AUTOSAR XML (schema 00054)
package /AUTOSAR/Platform/BaseTypes
  7 x base type, all with category=FIXED_LENGTH:
    boolean_bt: base-type-size=8, base-type-encoding=BOOLEAN
    uint8_bt: base-type-size=8, base-type-encoding=NONE
    uint16_bt: base-type-size=16, base-type-encoding=NONE
    uint32_bt: base-type-size=32, base-type-encoding=NONE
    sint8_bt: base-type-size=8, base-type-encoding=2C
    sint16_bt: base-type-size=16, base-type-encoding=2C
    sint32_bt: base-type-size=32, base-type-encoding=2C
package /AUTOSAR/Platform/ImplementationDataTypes
  7 x impl type, all with category=VALUE:
    boolean_T: base-type=boolean_bt
    uint8_T: base-type=uint8_bt
    uint16_T: base-type=uint16_bt
    uint32_T: base-type=uint32_bt
    sint8_T: base-type=sint8_bt
    sint16_T: base-type=sint16_bt
    sint32_T: base-type=sint32_bt
package /Taktflow/System
  system TaktflowSystem: category=SYSTEM_EXTRACT
package /Taktflow/Communication
  can cluster CAN_500k: baudrate=500000, protocol-name=CAN
    can physical channel CAN_Physical: comm-connectors=[CVC_Conn, FZC_Conn, RZC_Conn, SC_Conn, BCM_Conn, ICU_Conn, TCU_Conn, Tester_Conn, Plant_Sim_Conn]
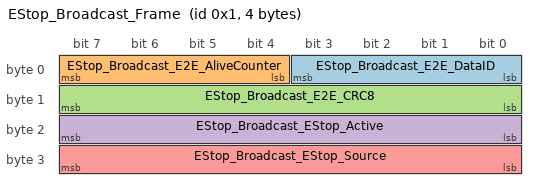
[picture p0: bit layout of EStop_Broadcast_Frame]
      frame EStop_Broadcast_Frame: id 0x1, frame-length=4, can-addressing-mode=STANDARD, can-frame-rx-behavior=CAN-20, can-frame-tx-behavior=CAN-20
        pdu EStop_Broadcast: length=4
          signal EStop_Broadcast_E2E_DataID: start 0, 4 bit, little-endian, data-type-policy=OVERRIDE, transfer-property=PENDING
          signal EStop_Broadcast_E2E_AliveCounter: start 4, 4 bit, little-endian, data-type-policy=OVERRIDE, transfer-property=PENDING
          signal EStop_Broadcast_E2E_CRC8: start 8, 8 bit, little-endian, data-type-policy=OVERRIDE, transfer-property=PENDING
          signal EStop_Broadcast_EStop_Active: start 16, 8 bit, little-endian, data-type-policy=OVERRIDE, transfer-property=PENDING
          signal EStop_Broadcast_EStop_Source: start 24, 8 bit, little-endian, data-type-policy=OVERRIDE, transfer-property=PENDING
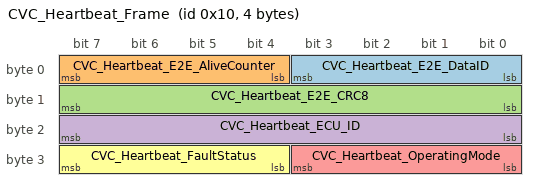
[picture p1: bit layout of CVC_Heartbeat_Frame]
      frame CVC_Heartbeat_Frame: id 0x10, frame-length=4, can-addressing-mode=STANDARD, can-frame-rx-behavior=CAN-20, can-frame-tx-behavior=CAN-20
        pdu CVC_Heartbeat: length=4
          signal CVC_Heartbeat_E2E_DataID: start 0, 4 bit, little-endian, data-type-policy=OVERRIDE, transfer-property=PENDING
          signal CVC_Heartbeat_E2E_AliveCounter: start 4, 4 bit, little-endian, data-type-policy=OVERRIDE, transfer-property=PENDING
          signal CVC_Heartbeat_E2E_CRC8: start 8, 8 bit, little-endian, data-type-policy=OVERRIDE, transfer-property=PENDING
          signal CVC_Heartbeat_ECU_ID: start 16, 8 bit, little-endian, data-type-policy=OVERRIDE, transfer-property=PENDING
          signal CVC_Heartbeat_OperatingMode: start 24, 4 bit, little-endian, data-type-policy=OVERRIDE, transfer-property=PENDING
          signal CVC_Heartbeat_FaultStatus: start 28, 4 bit, little-endian, data-type-policy=OVERRIDE, transfer-property=PENDING
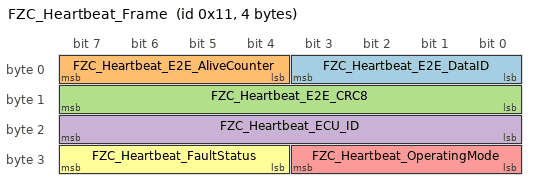
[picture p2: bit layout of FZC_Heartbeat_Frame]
      frame FZC_Heartbeat_Frame: id 0x11, frame-length=4, can-addressing-mode=STANDARD, can-frame-rx-behavior=CAN-20, can-frame-tx-behavior=CAN-20
        pdu FZC_Heartbeat: length=4
          signal FZC_Heartbeat_E2E_DataID: start 0, 4 bit, little-endian, data-type-policy=OVERRIDE, transfer-property=PENDING
          signal FZC_Heartbeat_E2E_AliveCounter: start 4, 4 bit, little-endian, data-type-policy=OVERRIDE, transfer-property=PENDING
          signal FZC_Heartbeat_E2E_CRC8: start 8, 8 bit, little-endian, data-type-policy=OVERRIDE, transfer-property=PENDING
          signal FZC_Heartbeat_ECU_ID: start 16, 8 bit, little-endian, data-type-policy=OVERRIDE, transfer-property=PENDING
          signal FZC_Heartbeat_OperatingMode: start 24, 4 bit, little-endian, data-type-policy=OVERRIDE, transfer-property=PENDING
          signal FZC_Heartbeat_FaultStatus: start 28, 4 bit, little-endian, data-type-policy=OVERRIDE, transfer-property=PENDING
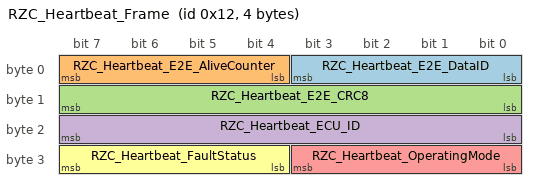
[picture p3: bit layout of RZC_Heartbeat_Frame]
      frame RZC_Heartbeat_Frame: id 0x12, frame-length=4, can-addressing-mode=STANDARD, can-frame-rx-behavior=CAN-20, can-frame-tx-behavior=CAN-20
        pdu RZC_Heartbeat: length=4
          signal RZC_Heartbeat_E2E_DataID: start 0, 4 bit, little-endian, data-type-policy=OVERRIDE, transfer-property=PENDING
          signal RZC_Heartbeat_E2E_AliveCounter: start 4, 4 bit, little-endian, data-type-policy=OVERRIDE, transfer-property=PENDING
          signal RZC_Heartbeat_E2E_CRC8: start 8, 8 bit, little-endian, data-type-policy=OVERRIDE, transfer-property=PENDING
          signal RZC_Heartbeat_ECU_ID: start 16, 8 bit, little-endian, data-type-policy=OVERRIDE, transfer-property=PENDING
          signal RZC_Heartbeat_OperatingMode: start 24, 4 bit, little-endian, data-type-policy=OVERRIDE, transfer-property=PENDING
          signal RZC_Heartbeat_FaultStatus: start 28, 4 bit, little-endian, data-type-policy=OVERRIDE, transfer-property=PENDING
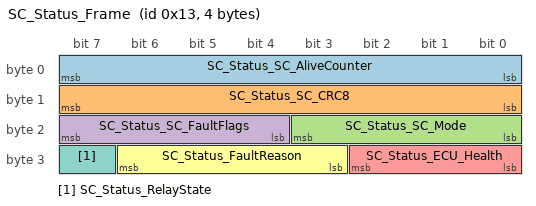
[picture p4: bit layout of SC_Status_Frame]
      frame SC_Status_Frame: id 0x13, frame-length=4, can-addressing-mode=STANDARD, can-frame-rx-behavior=CAN-20, can-frame-tx-behavior=CAN-20
        pdu SC_Status: length=4
          signal SC_Status_SC_AliveCounter: start 0, 8 bit, little-endian, data-type-policy=OVERRIDE, transfer-property=PENDING
          signal SC_Status_SC_CRC8: start 8, 8 bit, little-endian, data-type-policy=OVERRIDE, transfer-property=PENDING
          signal SC_Status_SC_Mode: start 16, 4 bit, little-endian, data-type-policy=OVERRIDE, transfer-property=PENDING
          signal SC_Status_SC_FaultFlags: start 20, 4 bit, little-endian, data-type-policy=OVERRIDE, transfer-property=PENDING
          signal SC_Status_ECU_Health: start 24, 3 bit, little-endian, data-type-policy=OVERRIDE, transfer-property=PENDING
          signal SC_Status_FaultReason: start 27, 4 bit, little-endian, data-type-policy=OVERRIDE, transfer-property=PENDING
          signal SC_Status_RelayState: start 31, 1 bit, little-endian, data-type-policy=OVERRIDE, transfer-property=PENDING
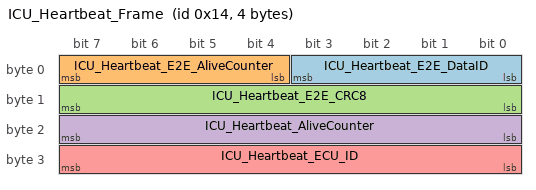
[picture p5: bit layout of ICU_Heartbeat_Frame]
      frame ICU_Heartbeat_Frame: id 0x14, frame-length=4, can-addressing-mode=STANDARD, can-frame-rx-behavior=CAN-20, can-frame-tx-behavior=CAN-20
        pdu ICU_Heartbeat: length=4
          signal ICU_Heartbeat_E2E_DataID: start 0, 4 bit, little-endian, data-type-policy=OVERRIDE, transfer-property=PENDING
          signal ICU_Heartbeat_E2E_AliveCounter: start 4, 4 bit, little-endian, data-type-policy=OVERRIDE, transfer-property=PENDING
          signal ICU_Heartbeat_E2E_CRC8: start 8, 8 bit, little-endian, data-type-policy=OVERRIDE, transfer-property=PENDING
          signal ICU_Heartbeat_AliveCounter: start 16, 8 bit, little-endian, data-type-policy=OVERRIDE, transfer-property=PENDING
          signal ICU_Heartbeat_ECU_ID: start 24, 8 bit, little-endian, data-type-policy=OVERRIDE, transfer-property=PENDING
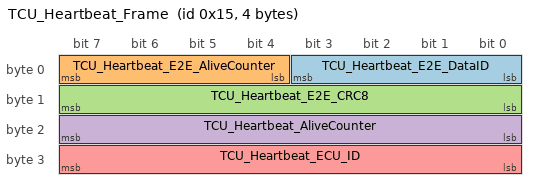
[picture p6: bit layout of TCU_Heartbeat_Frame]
      frame TCU_Heartbeat_Frame: id 0x15, frame-length=4, can-addressing-mode=STANDARD, can-frame-rx-behavior=CAN-20, can-frame-tx-behavior=CAN-20
        pdu TCU_Heartbeat: length=4
          signal TCU_Heartbeat_E2E_DataID: start 0, 4 bit, little-endian, data-type-policy=OVERRIDE, transfer-property=PENDING
          signal TCU_Heartbeat_E2E_AliveCounter: start 4, 4 bit, little-endian, data-type-policy=OVERRIDE, transfer-property=PENDING
          signal TCU_Heartbeat_E2E_CRC8: start 8, 8 bit, little-endian, data-type-policy=OVERRIDE, transfer-property=PENDING
          signal TCU_Heartbeat_AliveCounter: start 16, 8 bit, little-endian, data-type-policy=OVERRIDE, transfer-property=PENDING
          signal TCU_Heartbeat_ECU_ID: start 24, 8 bit, little-endian, data-type-policy=OVERRIDE, transfer-property=PENDING
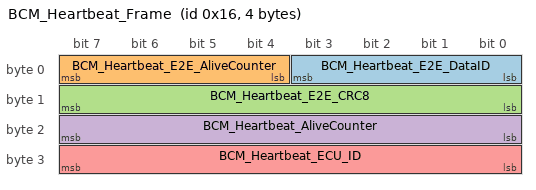
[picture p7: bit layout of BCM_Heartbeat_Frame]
      frame BCM_Heartbeat_Frame: id 0x16, frame-length=4, can-addressing-mode=STANDARD, can-frame-rx-behavior=CAN-20, can-frame-tx-behavior=CAN-20
        pdu BCM_Heartbeat: length=4
          signal BCM_Heartbeat_E2E_DataID: start 0, 4 bit, little-endian, data-type-policy=OVERRIDE, transfer-property=PENDING
          signal BCM_Heartbeat_E2E_AliveCounter: start 4, 4 bit, little-endian, data-type-policy=OVERRIDE, transfer-property=PENDING
          signal BCM_Heartbeat_E2E_CRC8: start 8, 8 bit, little-endian, data-type-policy=OVERRIDE, transfer-property=PENDING
          signal BCM_Heartbeat_AliveCounter: start 16, 8 bit, little-endian, data-type-policy=OVERRIDE, transfer-property=PENDING
          signal BCM_Heartbeat_ECU_ID: start 24, 8 bit, little-endian, data-type-policy=OVERRIDE, transfer-property=PENDING
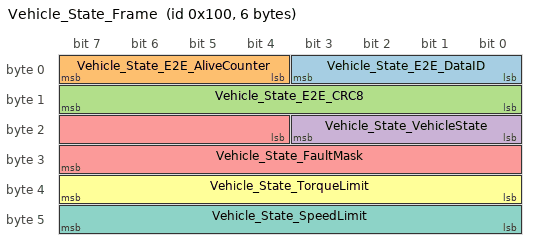
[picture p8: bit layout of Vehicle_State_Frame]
      frame Vehicle_State_Frame: id 0x100, frame-length=6, can-addressing-mode=STANDARD, can-frame-rx-behavior=CAN-20, can-frame-tx-behavior=CAN-20
        pdu Vehicle_State: length=6
          signal Vehicle_State_E2E_DataID: start 0, 4 bit, little-endian, data-type-policy=OVERRIDE, transfer-property=PENDING
          signal Vehicle_State_E2E_AliveCounter: start 4, 4 bit, little-endian, data-type-policy=OVERRIDE, transfer-property=PENDING
          signal Vehicle_State_E2E_CRC8: start 8, 8 bit, little-endian, data-type-policy=OVERRIDE, transfer-property=PENDING
          signal Vehicle_State_VehicleState: start 16, 4 bit, little-endian, data-type-policy=OVERRIDE, transfer-property=PENDING
          signal Vehicle_State_FaultMask: start 20, 12 bit, little-endian, data-type-policy=OVERRIDE, transfer-property=PENDING
          signal Vehicle_State_TorqueLimit: start 32, 8 bit, little-endian, data-type-policy=OVERRIDE, transfer-property=PENDING
          signal Vehicle_State_SpeedLimit: start 40, 8 bit, little-endian, data-type-policy=OVERRIDE, transfer-property=PENDING
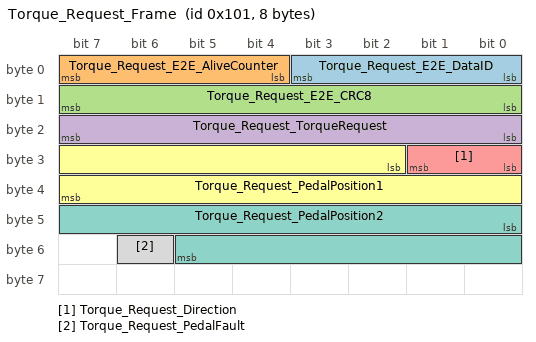
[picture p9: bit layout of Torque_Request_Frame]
      frame Torque_Request_Frame: id 0x101, frame-length=8, can-addressing-mode=STANDARD, can-frame-rx-behavior=CAN-20, can-frame-tx-behavior=CAN-20
        pdu Torque_Request: length=8
          signal Torque_Request_E2E_DataID: start 0, 4 bit, little-endian, data-type-policy=OVERRIDE, transfer-property=PENDING
          signal Torque_Request_E2E_AliveCounter: start 4, 4 bit, little-endian, data-type-policy=OVERRIDE, transfer-property=PENDING
          signal Torque_Request_E2E_CRC8: start 8, 8 bit, little-endian, data-type-policy=OVERRIDE, transfer-property=PENDING
          signal Torque_Request_TorqueRequest: start 16, 8 bit, little-endian, data-type-policy=OVERRIDE, transfer-property=PENDING
          signal Torque_Request_Direction: start 24, 2 bit, little-endian, data-type-policy=OVERRIDE, transfer-property=PENDING
          signal Torque_Request_PedalPosition1: start 26, 14 bit, little-endian, data-type-policy=OVERRIDE, transfer-property=PENDING
          signal Torque_Request_PedalPosition2: start 40, 14 bit, little-endian, data-type-policy=OVERRIDE, transfer-property=PENDING
          signal Torque_Request_PedalFault: start 54, 1 bit, little-endian, data-type-policy=OVERRIDE, transfer-property=PENDING
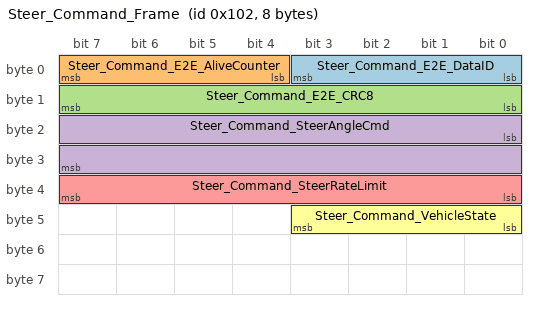
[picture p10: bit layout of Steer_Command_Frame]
      frame Steer_Command_Frame: id 0x102, frame-length=8, can-addressing-mode=STANDARD, can-frame-rx-behavior=CAN-20, can-frame-tx-behavior=CAN-20
        pdu Steer_Command: length=8
          signal Steer_Command_E2E_DataID: start 0, 4 bit, little-endian, data-type-policy=OVERRIDE, transfer-property=PENDING
          signal Steer_Command_E2E_AliveCounter: start 4, 4 bit, little-endian, data-type-policy=OVERRIDE, transfer-property=PENDING
          signal Steer_Command_E2E_CRC8: start 8, 8 bit, little-endian, data-type-policy=OVERRIDE, transfer-property=PENDING
          signal Steer_Command_SteerAngleCmd: start 16, 16 bit, little-endian, data-type-policy=OVERRIDE, transfer-property=PENDING
          signal Steer_Command_SteerRateLimit: start 32, 8 bit, little-endian, data-type-policy=OVERRIDE, transfer-property=PENDING
          signal Steer_Command_VehicleState: start 40, 4 bit, little-endian, data-type-policy=OVERRIDE, transfer-property=PENDING
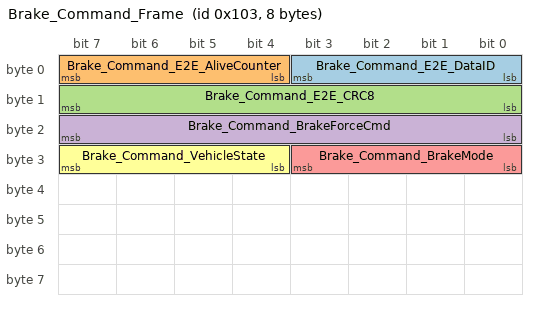
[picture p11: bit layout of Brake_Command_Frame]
      frame Brake_Command_Frame: id 0x103, frame-length=8, can-addressing-mode=STANDARD, can-frame-rx-behavior=CAN-20, can-frame-tx-behavior=CAN-20
        pdu Brake_Command: length=8
          signal Brake_Command_E2E_DataID: start 0, 4 bit, little-endian, data-type-policy=OVERRIDE, transfer-property=PENDING
          signal Brake_Command_E2E_AliveCounter: start 4, 4 bit, little-endian, data-type-policy=OVERRIDE, transfer-property=PENDING
          signal Brake_Command_E2E_CRC8: start 8, 8 bit, little-endian, data-type-policy=OVERRIDE, transfer-property=PENDING
          signal Brake_Command_BrakeForceCmd: start 16, 8 bit, little-endian, data-type-policy=OVERRIDE, transfer-property=PENDING
          signal Brake_Command_BrakeMode: start 24, 4 bit, little-endian, data-type-policy=OVERRIDE, transfer-property=PENDING
          signal Brake_Command_VehicleState: start 28, 4 bit, little-endian, data-type-policy=OVERRIDE, transfer-property=PENDING
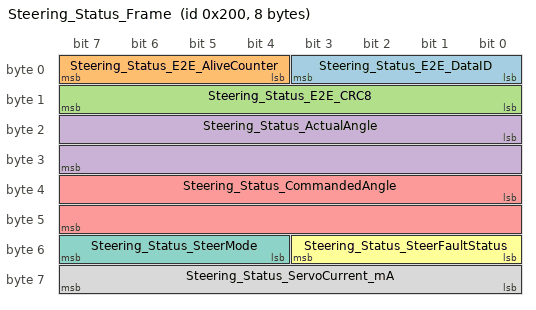
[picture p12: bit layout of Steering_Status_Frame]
      frame Steering_Status_Frame: id 0x200, frame-length=8, can-addressing-mode=STANDARD, can-frame-rx-behavior=CAN-20, can-frame-tx-behavior=CAN-20
        pdu Steering_Status: length=8
          signal Steering_Status_E2E_DataID: start 0, 4 bit, little-endian, data-type-policy=OVERRIDE, transfer-property=PENDING
          signal Steering_Status_E2E_AliveCounter: start 4, 4 bit, little-endian, data-type-policy=OVERRIDE, transfer-property=PENDING
          signal Steering_Status_E2E_CRC8: start 8, 8 bit, little-endian, data-type-policy=OVERRIDE, transfer-property=PENDING
          signal Steering_Status_ActualAngle: start 16, 16 bit, little-endian, data-type-policy=OVERRIDE, transfer-property=PENDING
          signal Steering_Status_CommandedAngle: start 32, 16 bit, little-endian, data-type-policy=OVERRIDE, transfer-property=PENDING
          signal Steering_Status_SteerFaultStatus: start 48, 4 bit, little-endian, data-type-policy=OVERRIDE, transfer-property=PENDING
          signal Steering_Status_SteerMode: start 52, 4 bit, little-endian, data-type-policy=OVERRIDE, transfer-property=PENDING
          signal Steering_Status_ServoCurrent_mA: start 56, 8 bit, little-endian, data-type-policy=OVERRIDE, transfer-property=PENDING
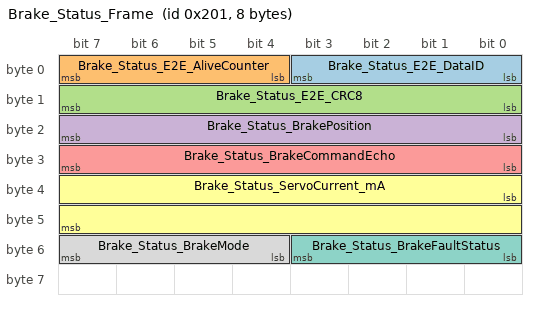
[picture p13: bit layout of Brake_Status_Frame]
      frame Brake_Status_Frame: id 0x201, frame-length=8, can-addressing-mode=STANDARD, can-frame-rx-behavior=CAN-20, can-frame-tx-behavior=CAN-20
        pdu Brake_Status: length=8
          signal Brake_Status_E2E_DataID: start 0, 4 bit, little-endian, data-type-policy=OVERRIDE, transfer-property=PENDING
          signal Brake_Status_E2E_AliveCounter: start 4, 4 bit, little-endian, data-type-policy=OVERRIDE, transfer-property=PENDING
          signal Brake_Status_E2E_CRC8: start 8, 8 bit, little-endian, data-type-policy=OVERRIDE, transfer-property=PENDING
          signal Brake_Status_BrakePosition: start 16, 8 bit, little-endian, data-type-policy=OVERRIDE, transfer-property=PENDING
          signal Brake_Status_BrakeCommandEcho: start 24, 8 bit, little-endian, data-type-policy=OVERRIDE, transfer-property=PENDING
          signal Brake_Status_ServoCurrent_mA: start 32, 16 bit, little-endian, data-type-policy=OVERRIDE, transfer-property=PENDING
          signal Brake_Status_BrakeFaultStatus: start 48, 4 bit, little-endian, data-type-policy=OVERRIDE, transfer-property=PENDING
          signal Brake_Status_BrakeMode: start 52, 4 bit, little-endian, data-type-policy=OVERRIDE, transfer-property=PENDING
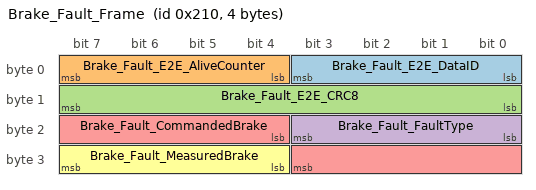
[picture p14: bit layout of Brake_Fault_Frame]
      frame Brake_Fault_Frame: id 0x210, frame-length=4, can-addressing-mode=STANDARD, can-frame-rx-behavior=CAN-20, can-frame-tx-behavior=CAN-20
        pdu Brake_Fault: length=4
          signal Brake_Fault_E2E_DataID: start 0, 4 bit, little-endian, data-type-policy=OVERRIDE, transfer-property=PENDING
          signal Brake_Fault_E2E_AliveCounter: start 4, 4 bit, little-endian, data-type-policy=OVERRIDE, transfer-property=PENDING
          signal Brake_Fault_E2E_CRC8: start 8, 8 bit, little-endian, data-type-policy=OVERRIDE, transfer-property=PENDING
          signal Brake_Fault_FaultType: start 16, 4 bit, little-endian, data-type-policy=OVERRIDE, transfer-property=PENDING
          signal Brake_Fault_CommandedBrake: start 20, 8 bit, little-endian, data-type-policy=OVERRIDE, transfer-property=PENDING
          signal Brake_Fault_MeasuredBrake: start 28, 4 bit, little-endian, data-type-policy=OVERRIDE, transfer-property=PENDING
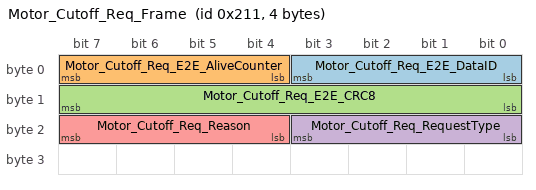
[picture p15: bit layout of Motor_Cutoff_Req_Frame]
      frame Motor_Cutoff_Req_Frame: id 0x211, frame-length=4, can-addressing-mode=STANDARD, can-frame-rx-behavior=CAN-20, can-frame-tx-behavior=CAN-20
        pdu Motor_Cutoff_Req: length=4
          signal Motor_Cutoff_Req_E2E_DataID: start 0, 4 bit, little-endian, data-type-policy=OVERRIDE, transfer-property=PENDING
          signal Motor_Cutoff_Req_E2E_AliveCounter: start 4, 4 bit, little-endian, data-type-policy=OVERRIDE, transfer-property=PENDING
          signal Motor_Cutoff_Req_E2E_CRC8: start 8, 8 bit, little-endian, data-type-policy=OVERRIDE, transfer-property=PENDING
          signal Motor_Cutoff_Req_RequestType: start 16, 4 bit, little-endian, data-type-policy=OVERRIDE, transfer-property=PENDING
          signal Motor_Cutoff_Req_Reason: start 20, 4 bit, little-endian, data-type-policy=OVERRIDE, transfer-property=PENDING
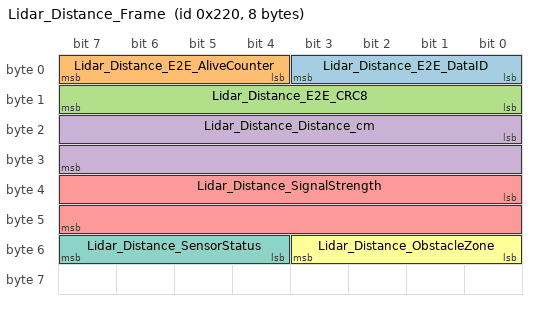
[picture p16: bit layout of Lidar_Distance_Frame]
      frame Lidar_Distance_Frame: id 0x220, frame-length=8, can-addressing-mode=STANDARD, can-frame-rx-behavior=CAN-20, can-frame-tx-behavior=CAN-20
        pdu Lidar_Distance: length=8
          signal Lidar_Distance_E2E_DataID: start 0, 4 bit, little-endian, data-type-policy=OVERRIDE, transfer-property=PENDING
          signal Lidar_Distance_E2E_AliveCounter: start 4, 4 bit, little-endian, data-type-policy=OVERRIDE, transfer-property=PENDING
          signal Lidar_Distance_E2E_CRC8: start 8, 8 bit, little-endian, data-type-policy=OVERRIDE, transfer-property=PENDING
          signal Lidar_Distance_Distance_cm: start 16, 16 bit, little-endian, data-type-policy=OVERRIDE, transfer-property=PENDING
          signal Lidar_Distance_SignalStrength: start 32, 16 bit, little-endian, data-type-policy=OVERRIDE, transfer-property=PENDING
          signal Lidar_Distance_ObstacleZone: start 48, 4 bit, little-endian, data-type-policy=OVERRIDE, transfer-property=PENDING
          signal Lidar_Distance_SensorStatus: start 52, 4 bit, little-endian, data-type-policy=OVERRIDE, transfer-property=PENDING
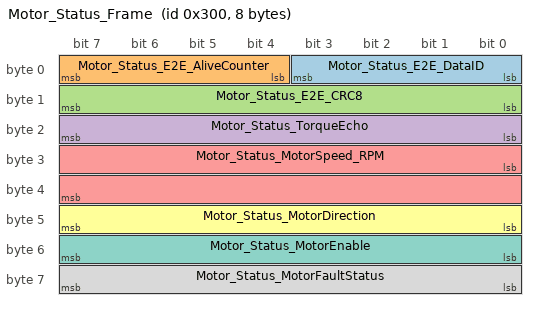
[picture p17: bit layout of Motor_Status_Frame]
      frame Motor_Status_Frame: id 0x300, frame-length=8, can-addressing-mode=STANDARD, can-frame-rx-behavior=CAN-20, can-frame-tx-behavior=CAN-20
        pdu Motor_Status: length=8
          signal Motor_Status_E2E_DataID: start 0, 4 bit, little-endian, data-type-policy=OVERRIDE, transfer-property=PENDING
          signal Motor_Status_E2E_AliveCounter: start 4, 4 bit, little-endian, data-type-policy=OVERRIDE, transfer-property=PENDING
          signal Motor_Status_E2E_CRC8: start 8, 8 bit, little-endian, data-type-policy=OVERRIDE, transfer-property=PENDING
          signal Motor_Status_TorqueEcho: start 16, 8 bit, little-endian, data-type-policy=OVERRIDE, transfer-property=PENDING
          signal Motor_Status_MotorSpeed_RPM: start 24, 16 bit, little-endian, data-type-policy=OVERRIDE, transfer-property=PENDING
          signal Motor_Status_MotorDirection: start 40, 8 bit, little-endian, data-type-policy=OVERRIDE, transfer-property=PENDING
          signal Motor_Status_MotorEnable: start 48, 8 bit, little-endian, data-type-policy=OVERRIDE, transfer-property=PENDING
          signal Motor_Status_MotorFaultStatus: start 56, 8 bit, little-endian, data-type-policy=OVERRIDE, transfer-property=PENDING
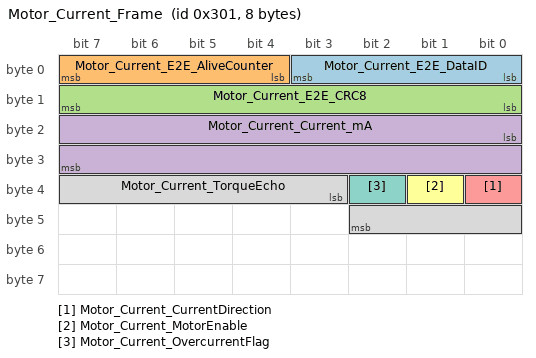
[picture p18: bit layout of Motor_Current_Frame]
      frame Motor_Current_Frame: id 0x301, frame-length=8, can-addressing-mode=STANDARD, can-frame-rx-behavior=CAN-20, can-frame-tx-behavior=CAN-20
        pdu Motor_Current: length=8
          signal Motor_Current_E2E_DataID: start 0, 4 bit, little-endian, data-type-policy=OVERRIDE, transfer-property=PENDING
          signal Motor_Current_E2E_AliveCounter: start 4, 4 bit, little-endian, data-type-policy=OVERRIDE, transfer-property=PENDING
          signal Motor_Current_E2E_CRC8: start 8, 8 bit, little-endian, data-type-policy=OVERRIDE, transfer-property=PENDING
          signal Motor_Current_Current_mA: start 16, 16 bit, little-endian, data-type-policy=OVERRIDE, transfer-property=PENDING
          signal Motor_Current_CurrentDirection: start 32, 1 bit, little-endian, data-type-policy=OVERRIDE, transfer-property=PENDING
          signal Motor_Current_MotorEnable: start 33, 1 bit, little-endian, data-type-policy=OVERRIDE, transfer-property=PENDING
          signal Motor_Current_OvercurrentFlag: start 34, 1 bit, little-endian, data-type-policy=OVERRIDE, transfer-property=PENDING
          signal Motor_Current_TorqueEcho: start 35, 8 bit, little-endian, data-type-policy=OVERRIDE, transfer-property=PENDING
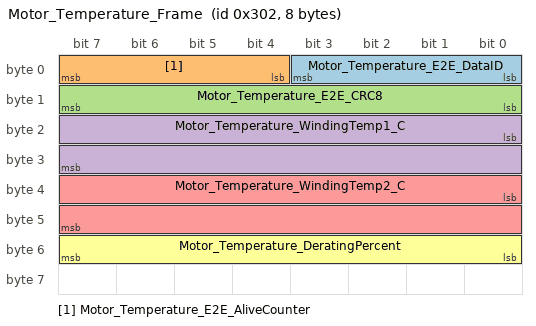
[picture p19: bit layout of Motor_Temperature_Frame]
      frame Motor_Temperature_Frame: id 0x302, frame-length=8, can-addressing-mode=STANDARD, can-frame-rx-behavior=CAN-20, can-frame-tx-behavior=CAN-20
        pdu Motor_Temperature: length=8
          signal Motor_Temperature_E2E_DataID: start 0, 4 bit, little-endian, data-type-policy=OVERRIDE, transfer-property=PENDING
          signal Motor_Temperature_E2E_AliveCounter: start 4, 4 bit, little-endian, data-type-policy=OVERRIDE, transfer-property=PENDING
          signal Motor_Temperature_E2E_CRC8: start 8, 8 bit, little-endian, data-type-policy=OVERRIDE, transfer-property=PENDING
          signal Motor_Temperature_WindingTemp1_C: start 16, 16 bit, little-endian, data-type-policy=OVERRIDE, transfer-property=PENDING
          signal Motor_Temperature_WindingTemp2_C: start 32, 16 bit, little-endian, data-type-policy=OVERRIDE, transfer-property=PENDING
          signal Motor_Temperature_DeratingPercent: start 48, 8 bit, little-endian, data-type-policy=OVERRIDE, transfer-property=PENDING
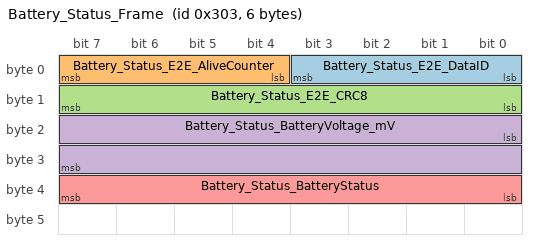
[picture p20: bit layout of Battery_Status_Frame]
      frame Battery_Status_Frame: id 0x303, frame-length=6, can-addressing-mode=STANDARD, can-frame-rx-behavior=CAN-20, can-frame-tx-behavior=CAN-20
        pdu Battery_Status: length=6
          signal Battery_Status_E2E_DataID: start 0, 4 bit, little-endian, data-type-policy=OVERRIDE, transfer-property=PENDING
          signal Battery_Status_E2E_AliveCounter: start 4, 4 bit, little-endian, data-type-policy=OVERRIDE, transfer-property=PENDING
          signal Battery_Status_E2E_CRC8: start 8, 8 bit, little-endian, data-type-policy=OVERRIDE, transfer-property=PENDING
          signal Battery_Status_BatteryVoltage_mV: start 16, 16 bit, little-endian, data-type-policy=OVERRIDE, transfer-property=PENDING
          signal Battery_Status_BatteryStatus: start 32, 8 bit, little-endian, data-type-policy=OVERRIDE, transfer-property=PENDING
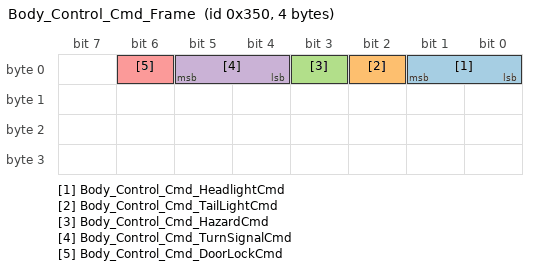
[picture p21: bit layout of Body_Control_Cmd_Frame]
      frame Body_Control_Cmd_Frame: id 0x350, frame-length=4, can-addressing-mode=STANDARD, can-frame-rx-behavior=CAN-20, can-frame-tx-behavior=CAN-20
        pdu Body_Control_Cmd: length=4
          signal Body_Control_Cmd_HeadlightCmd: start 0, 2 bit, little-endian, data-type-policy=OVERRIDE, transfer-property=PENDING
          signal Body_Control_Cmd_TailLightCmd: start 2, 1 bit, little-endian, data-type-policy=OVERRIDE, transfer-property=PENDING
          signal Body_Control_Cmd_HazardCmd: start 3, 1 bit, little-endian, data-type-policy=OVERRIDE, transfer-property=PENDING
          signal Body_Control_Cmd_TurnSignalCmd: start 4, 2 bit, little-endian, data-type-policy=OVERRIDE, transfer-property=PENDING
          signal Body_Control_Cmd_DoorLockCmd: start 6, 1 bit, little-endian, data-type-policy=OVERRIDE, transfer-property=PENDING
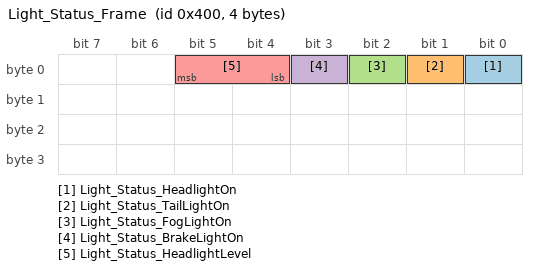
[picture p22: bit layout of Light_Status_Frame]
      frame Light_Status_Frame: id 0x400, frame-length=4, can-addressing-mode=STANDARD, can-frame-rx-behavior=CAN-20, can-frame-tx-behavior=CAN-20
        pdu Light_Status: length=4
          signal Light_Status_HeadlightOn: start 0, 1 bit, little-endian, data-type-policy=OVERRIDE, transfer-property=PENDING
          signal Light_Status_TailLightOn: start 1, 1 bit, little-endian, data-type-policy=OVERRIDE, transfer-property=PENDING
          signal Light_Status_FogLightOn: start 2, 1 bit, little-endian, data-type-policy=OVERRIDE, transfer-property=PENDING
          signal Light_Status_BrakeLightOn: start 3, 1 bit, little-endian, data-type-policy=OVERRIDE, transfer-property=PENDING
          signal Light_Status_HeadlightLevel: start 4, 2 bit, little-endian, data-type-policy=OVERRIDE, transfer-property=PENDING
      frame Indicator_State_Frame: id 0x401, frame-length=4, can-addressing-mode=STANDARD, can-frame-rx-behavior=CAN-20, can-frame-tx-behavior=CAN-20
        pdu Indicator_State: length=4
          signal Indicator_State_LeftIndicator: start 0, 1 bit, little-endian, data-type-policy=OVERRIDE, transfer-property=PENDING
          signal Indicator_State_RightIndicator: start 1, 1 bit, little-endian, data-type-policy=OVERRIDE, transfer-property=PENDING
          signal Indicator_State_HazardActive: start 2, 1 bit, little-endian, data-type-policy=OVERRIDE, transfer-property=PENDING
          signal Indicator_State_BlinkState: start 3, 1 bit, little-endian, data-type-policy=OVERRIDE, transfer-property=PENDING
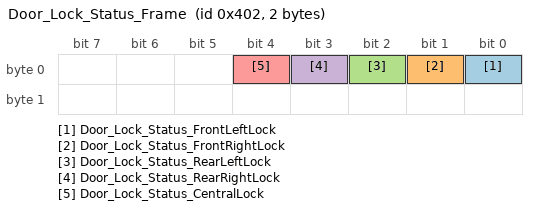
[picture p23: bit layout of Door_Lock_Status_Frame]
      frame Door_Lock_Status_Frame: id 0x402, frame-length=2, can-addressing-mode=STANDARD, can-frame-rx-behavior=CAN-20, can-frame-tx-behavior=CAN-20
        pdu Door_Lock_Status: length=2
          signal Door_Lock_Status_FrontLeftLock: start 0, 1 bit, little-endian, data-type-policy=OVERRIDE, transfer-property=PENDING
          signal Door_Lock_Status_FrontRightLock: start 1, 1 bit, little-endian, data-type-policy=OVERRIDE, transfer-property=PENDING
          signal Door_Lock_Status_RearLeftLock: start 2, 1 bit, little-endian, data-type-policy=OVERRIDE, transfer-property=PENDING
          signal Door_Lock_Status_RearRightLock: start 3, 1 bit, little-endian, data-type-policy=OVERRIDE, transfer-property=PENDING
          signal Door_Lock_Status_CentralLock: start 4, 1 bit, little-endian, data-type-policy=OVERRIDE, transfer-property=PENDING
      frame DTC_Broadcast_Frame: id 0x500, frame-length=8, can-addressing-mode=STANDARD, can-frame-rx-behavior=CAN-20, can-frame-tx-behavior=CAN-20
        pdu DTC_Broadcast: length=8
          signal DTC_Broadcast_DTC_Number: start 7, 24 bit, big-endian, data-type-policy=OVERRIDE, transfer-property=PENDING
          signal DTC_Broadcast_DTC_Status: start 24, 8 bit, little-endian, data-type-policy=OVERRIDE, transfer-property=PENDING
          signal DTC_Broadcast_ECU_Source: start 32, 8 bit, little-endian, data-type-policy=OVERRIDE, transfer-property=PENDING
          signal DTC_Broadcast_OccurrenceCount: start 40, 8 bit, little-endian, data-type-policy=OVERRIDE, transfer-property=PENDING
          signal DTC_Broadcast_FreezeFrame0: start 48, 8 bit, little-endian, data-type-policy=OVERRIDE, transfer-property=PENDING
          signal DTC_Broadcast_FreezeFrame1: start 56, 8 bit, little-endian, data-type-policy=OVERRIDE, transfer-property=PENDING
      frame UDS_Func_Request_Frame: id 0x7DF, frame-length=8, can-addressing-mode=STANDARD, can-frame-rx-behavior=CAN-20, can-frame-tx-behavior=CAN-20
        pdu UDS_Func_Request: length=8
          signal UDS_Func_Request_UDS_Data: start 0, 64 bit, little-endian, data-type-policy=OVERRIDE, transfer-property=PENDING
      frame UDS_Phys_Req_CVC_Frame: id 0x7E0, frame-length=8, can-addressing-mode=STANDARD, can-frame-rx-behavior=CAN-20, can-frame-tx-behavior=CAN-20
        pdu UDS_Phys_Req_CVC: length=8
          signal UDS_Phys_Req_CVC_UDS_Data: start 0, 64 bit, little-endian, data-type-policy=OVERRIDE, transfer-property=PENDING
      frame UDS_Phys_Req_FZC_Frame: id 0x7E1, frame-length=8, can-addressing-mode=STANDARD, can-frame-rx-behavior=CAN-20, can-frame-tx-behavior=CAN-20
        pdu UDS_Phys_Req_FZC: length=8
          signal UDS_Phys_Req_FZC_UDS_Data: start 0, 64 bit, little-endian, data-type-policy=OVERRIDE, transfer-property=PENDING
      frame UDS_Phys_Req_RZC_Frame: id 0x7E2, frame-length=8, can-addressing-mode=STANDARD, can-frame-rx-behavior=CAN-20, can-frame-tx-behavior=CAN-20
        pdu UDS_Phys_Req_RZC: length=8
          signal UDS_Phys_Req_RZC_UDS_Data: start 0, 64 bit, little-endian, data-type-policy=OVERRIDE, transfer-property=PENDING
      frame UDS_Phys_Req_TCU_Frame: id 0x7E3, frame-length=8, can-addressing-mode=STANDARD, can-frame-rx-behavior=CAN-20, can-frame-tx-behavior=CAN-20
        pdu UDS_Phys_Req_TCU: length=8
          signal UDS_Phys_Req_TCU_UDS_Data: start 0, 64 bit, little-endian, data-type-policy=OVERRIDE, transfer-property=PENDING
      frame UDS_Resp_CVC_Frame: id 0x7E8, frame-length=8, can-addressing-mode=STANDARD, can-frame-rx-behavior=CAN-20, can-frame-tx-behavior=CAN-20
        pdu UDS_Resp_CVC: length=8
          signal UDS_Resp_CVC_UDS_Data: start 0, 64 bit, little-endian, data-type-policy=OVERRIDE, transfer-property=PENDING
      frame UDS_Resp_FZC_Frame: id 0x7E9, frame-length=8, can-addressing-mode=STANDARD, can-frame-rx-behavior=CAN-20, can-frame-tx-behavior=CAN-20
        pdu UDS_Resp_FZC: length=8
          signal UDS_Resp_FZC_UDS_Data: start 0, 64 bit, little-endian, data-type-policy=OVERRIDE, transfer-property=PENDING
      frame UDS_Resp_RZC_Frame: id 0x7EA, frame-length=8, can-addressing-mode=STANDARD, can-frame-rx-behavior=CAN-20, can-frame-tx-behavior=CAN-20
        pdu UDS_Resp_RZC: length=8
          signal UDS_Resp_RZC_UDS_Data: start 0, 64 bit, little-endian, data-type-policy=OVERRIDE, transfer-property=PENDING
      frame UDS_Resp_TCU_Frame: id 0x644, frame-length=8, can-addressing-mode=STANDARD, can-frame-rx-behavior=CAN-20, can-frame-tx-behavior=CAN-20
        pdu UDS_Resp_TCU: length=8
          signal UDS_Resp_TCU_UDS_Data: start 0, 64 bit, little-endian, data-type-policy=OVERRIDE, transfer-property=PENDING
      frame FZC_Virtual_Sensors_Frame: id 0x600, frame-length=8, can-addressing-mode=STANDARD, can-frame-rx-behavior=CAN-20, can-frame-tx-behavior=CAN-20
        pdu FZC_Virtual_Sensors: length=8
          signal FZC_Virtual_Sensors_VSensor_SteerAngle_Raw: start 0, 16 bit, little-endian, data-type-policy=OVERRIDE, transfer-property=PENDING
          signal FZC_Virtual_Sensors_VSensor_BrakePos_ADC: start 16, 16 bit, little-endian, data-type-policy=OVERRIDE, transfer-property=PENDING
          signal FZC_Virtual_Sensors_VSensor_BrakeCurrent: start 32, 16 bit, little-endian, data-type-policy=OVERRIDE, transfer-property=PENDING
      frame RZC_Virtual_Sensors_Frame: id 0x601, frame-length=8, can-addressing-mode=STANDARD, can-frame-rx-behavior=CAN-20, can-frame-tx-behavior=CAN-20
        pdu RZC_Virtual_Sensors: length=8
          signal RZC_Virtual_Sensors_VSensor_MotorCurrent: start 0, 16 bit, little-endian, data-type-policy=OVERRIDE, transfer-property=PENDING
          signal RZC_Virtual_Sensors_VSensor_MotorTemp_dC: start 16, 16 bit, little-endian, data-type-policy=OVERRIDE, transfer-property=PENDING
          signal RZC_Virtual_Sensors_VSensor_BattVoltage: start 32, 16 bit, little-endian, data-type-policy=OVERRIDE, transfer-property=PENDING
          signal RZC_Virtual_Sensors_VSensor_MotorRPM: start 48, 16 bit, little-endian, data-type-policy=OVERRIDE, transfer-property=PENDING
package /Taktflow/ECUs
  9 x ecu instance:
    CVC
      can communication controller CVC_CanCtrl
      can communication connector CVC_Conn: comm-controller=CVC_CanCtrl
    FZC
      can communication controller FZC_CanCtrl
      can communication connector FZC_Conn: comm-controller=FZC_CanCtrl
    RZC
      can communication controller RZC_CanCtrl
      can communication connector RZC_Conn: comm-controller=RZC_CanCtrl
    SC
      can communication controller SC_CanCtrl
      can communication connector SC_Conn: comm-controller=SC_CanCtrl
    BCM
      can communication controller BCM_CanCtrl
      can communication connector BCM_Conn: comm-controller=BCM_CanCtrl
    ICU
      can communication controller ICU_CanCtrl
      can communication connector ICU_Conn: comm-controller=ICU_CanCtrl
    TCU
      can communication controller TCU_CanCtrl
      can communication connector TCU_Conn: comm-controller=TCU_CanCtrl
    Tester
      can communication controller Tester_CanCtrl
      can communication connector Tester_Conn: comm-controller=Tester_CanCtrl
    Plant_Sim
      can communication controller Plant_Sim_CanCtrl
      can communication connector Plant_Sim_Conn: comm-controller=Plant_Sim_CanCtrl
package /Taktflow/DataTypes
  compu method CM_EStop_Source: 0=CVC_button, 1=CAN_request, 2=SC_relay
  compu method CM_OperatingMode: 0=INIT, 1=RUN, 2=DEGRADED, 3=LIMP, 4=SAFE_STOP, 5=SHUTDOWN
  compu method CM_SC_Mode: 0=INIT, 1=MONITORING, 2=FAULT_DETECTED, 3=SAFE_STOP
  compu method CM_VehicleState: 0=INIT, 1=RUN, 2=DEGRADED, 3=LIMP, 4=SAFE_STOP, 5=SHUTDOWN
  compu method CM_Direction: 0=stopped, 1=forward, 2=reverse
  compu method CM_PedalPosition1: phys=raw*0.022 for raw 0..359.98
  compu method CM_PedalPosition2: phys=raw*0.022 for raw 0..359.98
  compu method CM_SteerAngleCmd: phys=raw*0.01 for raw -45..45
  compu method CM_SteerRateLimit: phys=raw*0.2 for raw 0..51
  compu method CM_BrakeMode: 0=release, 1=normal, 2=emergency, 3=auto
  compu method CM_SteerMode: 0=normal, 1=return_center, 2=disabled, 3=local
  compu method CM_ServoCurrent_mA: phys=raw*10 for raw 0..2550
  compu method CM_FaultType: 0=PWM_mismatch, 1=servo_stuck, 2=overcurrent, 3=timeout
  compu method CM_MeasuredBrake: phys=raw*10 for raw 0..100
  compu method CM_RequestType: 0=motor_cutoff, 1=speed_reduce, 2=e_stop_fwd
  compu method CM_Reason: 0=brake_fault, 1=steer_fault, 2=lidar_emergency, 3=CAN_loss
  compu method CM_ObstacleZone: 0=emergency, 1=braking, 2=warning, 3=clear
  compu method CM_MotorDirection: 0=stopped, 1=forward, 2=reverse
  compu method CM_CurrentDirection: 0=forward, 1=reverse
  compu method CM_WindingTemp1_C: phys=raw*0.1 for raw 0..200
  compu method CM_WindingTemp2_C: phys=raw*0.1 for raw 0..200
  compu method CM_BatteryStatus: 0=critical_UV, 1=UV_warn, 2=normal, 3=OV_warn, 4=critical_OV
  compu method CM_HeadlightCmd: 0=off, 1=low, 2=high
  compu method CM_TurnSignalCmd: 0=off, 1=left, 2=right
  compu method CM_HeadlightLevel: 0=off, 1=low, 2=high
  compu method CM_ECU_Source: 1=CVC, 2=FZC, 3=RZC, 4=SC, 5=BCM, 6=ICU, 7=TCU
package /Taktflow/Interfaces
  92 x sender receiver interface:
    SRI_E2E_DataID
      data E2E_DataID: type=uint8_T
    SRI_E2E_AliveCounter
      data E2E_AliveCounter: type=uint8_T
    SRI_E2E_CRC8
      data E2E_CRC8: type=uint8_T
    SRI_EStop_Active
      data EStop_Active: type=uint8_T
    SRI_EStop_Source
      data EStop_Source: type=uint8_T
    SRI_ECU_ID
      data ECU_ID: type=uint8_T
    SRI_OperatingMode
      data OperatingMode: type=uint8_T
    SRI_FaultStatus
      data FaultStatus: type=uint8_T
    SRI_SC_AliveCounter
      data SC_AliveCounter: type=uint8_T
    SRI_SC_CRC8
      data SC_CRC8: type=uint8_T
    SRI_SC_Mode
      data SC_Mode: type=uint8_T
    SRI_SC_FaultFlags
      data SC_FaultFlags: type=uint8_T
    SRI_ECU_Health
      data ECU_Health: type=uint8_T
    SRI_FaultReason
      data FaultReason: type=uint8_T
    SRI_RelayState
      data RelayState: type=boolean_T
    SRI_AliveCounter
      data AliveCounter: type=uint8_T
    SRI_VehicleState
      data VehicleState: type=uint8_T
    SRI_FaultMask
      data FaultMask: type=uint16_T
    SRI_TorqueLimit
      data TorqueLimit: type=uint8_T
    SRI_SpeedLimit
      data SpeedLimit: type=uint8_T
    SRI_TorqueRequest
      data TorqueRequest: type=uint8_T
    SRI_Direction
      data Direction: type=uint8_T
    SRI_PedalPosition1
      data PedalPosition1: type=uint16_T
    SRI_PedalPosition2
      data PedalPosition2: type=uint16_T
    SRI_PedalFault
      data PedalFault: type=boolean_T
    SRI_SteerAngleCmd
      data SteerAngleCmd: type=sint16_T
    SRI_SteerRateLimit
      data SteerRateLimit: type=uint8_T
    SRI_BrakeForceCmd
      data BrakeForceCmd: type=uint8_T
    SRI_BrakeMode
      data BrakeMode: type=uint8_T
    SRI_ActualAngle
      data ActualAngle: type=sint16_T
    SRI_CommandedAngle
      data CommandedAngle: type=sint16_T
    SRI_SteerFaultStatus
      data SteerFaultStatus: type=uint8_T
    SRI_SteerMode
      data SteerMode: type=uint8_T
    SRI_ServoCurrent_mA
      data ServoCurrent_mA: type=uint8_T
    SRI_BrakePosition
      data BrakePosition: type=uint8_T
    SRI_BrakeCommandEcho
      data BrakeCommandEcho: type=uint8_T
    SRI_BrakeFaultStatus
      data BrakeFaultStatus: type=uint8_T
    SRI_FaultType
      data FaultType: type=uint8_T
    SRI_CommandedBrake
      data CommandedBrake: type=uint8_T
    SRI_MeasuredBrake
      data MeasuredBrake: type=uint8_T
    SRI_RequestType
      data RequestType: type=uint8_T
    SRI_Reason
      data Reason: type=uint8_T
    SRI_Distance_cm
      data Distance_cm: type=uint16_T
    SRI_SignalStrength
      data SignalStrength: type=uint16_T
    SRI_ObstacleZone
      data ObstacleZone: type=uint8_T
    SRI_SensorStatus
      data SensorStatus: type=uint8_T
    SRI_TorqueEcho
      data TorqueEcho: type=uint8_T
    SRI_MotorSpeed_RPM
      data MotorSpeed_RPM: type=uint16_T
    SRI_MotorDirection
      data MotorDirection: type=uint8_T
    SRI_MotorEnable
      data MotorEnable: type=uint8_T
    SRI_MotorFaultStatus
      data MotorFaultStatus: type=uint8_T
    SRI_Current_mA
      data Current_mA: type=uint16_T
    SRI_CurrentDirection
      data CurrentDirection: type=boolean_T
    SRI_OvercurrentFlag
      data OvercurrentFlag: type=boolean_T
    SRI_WindingTemp1_C
      data WindingTemp1_C: type=uint16_T
    SRI_WindingTemp2_C
      data WindingTemp2_C: type=uint16_T
    SRI_DeratingPercent
      data DeratingPercent: type=uint8_T
    SRI_BatteryVoltage_mV
      data BatteryVoltage_mV: type=uint16_T
    SRI_BatteryStatus
      data BatteryStatus: type=uint8_T
    SRI_HeadlightCmd
      data HeadlightCmd: type=uint8_T
    SRI_TailLightCmd
      data TailLightCmd: type=boolean_T
    SRI_HazardCmd
      data HazardCmd: type=boolean_T
    SRI_TurnSignalCmd
      data TurnSignalCmd: type=uint8_T
    SRI_DoorLockCmd
      data DoorLockCmd: type=boolean_T
    SRI_HeadlightOn
      data HeadlightOn: type=boolean_T
    SRI_TailLightOn
      data TailLightOn: type=boolean_T
    SRI_FogLightOn
      data FogLightOn: type=boolean_T
    SRI_BrakeLightOn
      data BrakeLightOn: type=boolean_T
    SRI_HeadlightLevel
      data HeadlightLevel: type=uint8_T
    SRI_LeftIndicator
      data LeftIndicator: type=boolean_T
    SRI_RightIndicator
      data RightIndicator: type=boolean_T
    SRI_HazardActive
      data HazardActive: type=boolean_T
    SRI_BlinkState
      data BlinkState: type=boolean_T
    SRI_FrontLeftLock
      data FrontLeftLock: type=boolean_T
    SRI_FrontRightLock
      data FrontRightLock: type=boolean_T
    SRI_RearLeftLock
      data RearLeftLock: type=boolean_T
    SRI_RearRightLock
      data RearRightLock: type=boolean_T
    SRI_CentralLock
      data CentralLock: type=boolean_T
    SRI_DTC_Number
      data DTC_Number: type=uint32_T
    SRI_DTC_Status
      data DTC_Status: type=uint8_T
    SRI_ECU_Source
      data ECU_Source: type=uint8_T
    SRI_OccurrenceCount
      data OccurrenceCount: type=uint8_T
    SRI_FreezeFrame0
      data FreezeFrame0: type=uint8_T
    SRI_FreezeFrame1
      data FreezeFrame1: type=uint8_T
    SRI_UDS_Data
      data UDS_Data: type=uint32_T
    SRI_VSensor_SteerAngle_Raw
      data VSensor_SteerAngle_Raw: type=uint16_T
    SRI_VSensor_BrakePos_ADC
      data VSensor_BrakePos_ADC: type=uint16_T
    SRI_VSensor_BrakeCurrent
      data VSensor_BrakeCurrent: type=uint16_T
    SRI_VSensor_MotorCurrent
      data VSensor_MotorCurrent: type=uint16_T
    SRI_VSensor_MotorTemp_dC
      data VSensor_MotorTemp_dC: type=uint16_T
    SRI_VSensor_BattVoltage
      data VSensor_BattVoltage: type=uint16_T
    SRI_VSensor_MotorRPM
      data VSensor_MotorRPM: type=uint16_T
package /Taktflow/E2E
  20 x system signal:
    E2E_EStop_Broadcast  # E2E Profile: DataID(4bit)+AliveCounter(4bit)+CRC8. CAN ID: 0x001. ASIL: B. Cycle: 10ms.
    E2E_CVC_Heartbeat  # E2E Profile: DataID(4bit)+AliveCounter(4bit)+CRC8. CAN ID: 0x010. ASIL: C. Cycle: 50ms.
    E2E_FZC_Heartbeat  # E2E Profile: DataID(4bit)+AliveCounter(4bit)+CRC8. CAN ID: 0x011. ASIL: C. Cycle: 50ms.
    E2E_RZC_Heartbeat  # E2E Profile: DataID(4bit)+AliveCounter(4bit)+CRC8. CAN ID: 0x012. ASIL: C. Cycle: 50ms.
    E2E_ICU_Heartbeat  # E2E Profile: DataID(4bit)+AliveCounter(4bit)+CRC8. CAN ID: 0x014. ASIL: QM. Cycle: 500ms.
    E2E_TCU_Heartbeat  # E2E Profile: DataID(4bit)+AliveCounter(4bit)+CRC8. CAN ID: 0x015. ASIL: QM. Cycle: 500ms.
    E2E_BCM_Heartbeat  # E2E Profile: DataID(4bit)+AliveCounter(4bit)+CRC8. CAN ID: 0x016. ASIL: QM. Cycle: ?ms.
    E2E_Vehicle_State  # E2E Profile: DataID(4bit)+AliveCounter(4bit)+CRC8. CAN ID: 0x100. ASIL: D. Cycle: 10ms.
    E2E_Torque_Request  # E2E Profile: DataID(4bit)+AliveCounter(4bit)+CRC8. CAN ID: 0x101. ASIL: D. Cycle: 10ms.
    E2E_Steer_Command  # E2E Profile: DataID(4bit)+AliveCounter(4bit)+CRC8. CAN ID: 0x102. ASIL: D. Cycle: 10ms.
    E2E_Brake_Command  # E2E Profile: DataID(4bit)+AliveCounter(4bit)+CRC8. CAN ID: 0x103. ASIL: D. Cycle: 10ms.
    E2E_Steering_Status  # E2E Profile: DataID(4bit)+AliveCounter(4bit)+CRC8. CAN ID: 0x200. ASIL: D. Cycle: 20ms.
    E2E_Brake_Status  # E2E Profile: DataID(4bit)+AliveCounter(4bit)+CRC8. CAN ID: 0x201. ASIL: D. Cycle: 20ms.
    E2E_Brake_Fault  # E2E Profile: DataID(4bit)+AliveCounter(4bit)+CRC8. CAN ID: 0x210. ASIL: D. Cycle: 0ms.
    E2E_Motor_Cutoff_Req  # E2E Profile: DataID(4bit)+AliveCounter(4bit)+CRC8. CAN ID: 0x211. ASIL: D. Cycle: 10ms.
    E2E_Lidar_Distance  # E2E Profile: DataID(4bit)+AliveCounter(4bit)+CRC8. CAN ID: 0x220. ASIL: C. Cycle: 10ms.
    E2E_Motor_Status  # E2E Profile: DataID(4bit)+AliveCounter(4bit)+CRC8. CAN ID: 0x300. ASIL: D. Cycle: 20ms.
    E2E_Motor_Current  # E2E Profile: DataID(4bit)+AliveCounter(4bit)+CRC8. CAN ID: 0x301. ASIL: C. Cycle: 10ms.
    E2E_Motor_Temperature  # E2E Profile: DataID(4bit)+AliveCounter(4bit)+CRC8. CAN ID: 0x302. ASIL: A. Cycle: 100ms.
    E2E_Battery_Status  # E2E Profile: DataID(4bit)+AliveCounter(4bit)+CRC8. CAN ID: 0x303. ASIL: QM. Cycle: 1000ms.
